AUTOSAR XML (schema 4-0-3)
standard types defined: Boolean, UInt32, UInt8
package /AUTOSAR_Platform/DataConstrs
  range DC_Boolean: raw 0..1
  range DC_UInt8: raw 0..255
package /PATAC/MSM/ComponentTypes
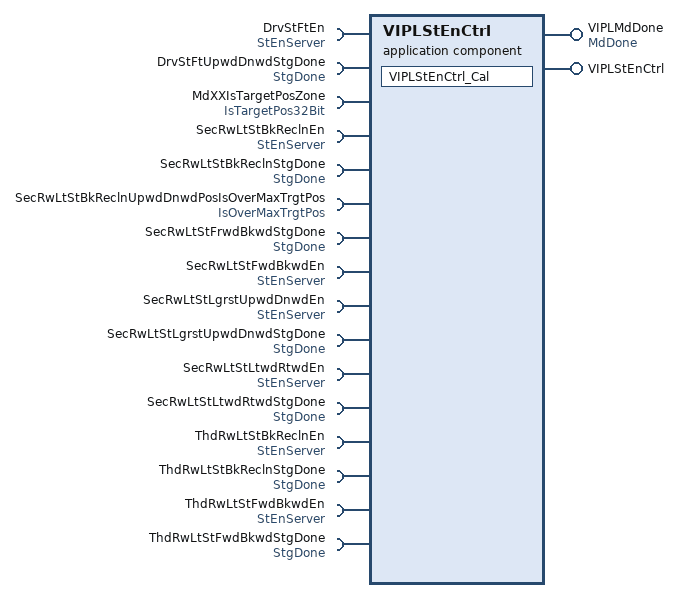
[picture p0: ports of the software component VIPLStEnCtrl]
  application sw component type VIPLStEnCtrl
    provide port VIPLMdDone: nonqueued-sender-com-spec{data-element=MdDone/Val, init-value=0}, provided-interface=MdDone
    provide port VIPLStEnCtrl: server-com-spec{operation=Cal, queue-length=1}, provided-interface=VIPLStEnCtrl
    16 x require port:
      DrvStFtEn: required-com-specs=[Clear, Get, Set], required-interface=StEnServer
      DrvStFtUpwdDnwdStgDone: nonqueued-receiver-com-spec{data-element=StgDone/Val, filter=data-filter-type=ALWAYS, init-value=0}, required-interface=StgDone
      MdXXIsTargetPosZone: nonqueued-receiver-com-spec{data-element=IsTargetPos32Bit/Val, filter=data-filter-type=ALWAYS, init-value=0}, required-interface=IsTargetPos32Bit
      SecRwLtStBkReclnEn: required-com-specs=[Clear, Get, Set], required-interface=StEnServer
      SecRwLtStBkReclnStgDone: nonqueued-receiver-com-spec{data-element=StgDone/Val, filter=data-filter-type=ALWAYS, init-value=0}, required-interface=StgDone
      SecRwLtStBkReclnUpwdDnwdPosIsOverMaxTrgtPos: nonqueued-receiver-com-spec{data-element=IsOverMaxTrgtPos/Val, filter=data-filter-type=ALWAYS, init-value=0}, required-interface=IsOverMaxTrgtPos
      SecRwLtStFrwdBkwdStgDone: nonqueued-receiver-com-spec{data-element=StgDone/Val, filter=data-filter-type=ALWAYS, init-value=0}, required-interface=StgDone
      SecRwLtStFwdBkwdEn: required-com-specs=[Clear, Get, Set], required-interface=StEnServer
      SecRwLtStLgrstUpwdDnwdEn: required-com-specs=[Clear, Get, Set], required-interface=StEnServer
      SecRwLtStLgrstUpwdDnwdStgDone: nonqueued-receiver-com-spec{data-element=StgDone/Val, filter=data-filter-type=ALWAYS, init-value=0}, required-interface=StgDone
      SecRwLtStLtwdRtwdEn: required-com-specs=[Clear, Get, Set], required-interface=StEnServer
      SecRwLtStLtwdRtwdStgDone: nonqueued-receiver-com-spec{data-element=StgDone/Val, filter=data-filter-type=ALWAYS, init-value=0}, required-interface=StgDone
      ThdRwLtStBkReclnEn: required-com-specs=[Clear, Get, Set], required-interface=StEnServer
      ThdRwLtStBkReclnStgDone: nonqueued-receiver-com-spec{data-element=StgDone/Val, filter=data-filter-type=ALWAYS, init-value=0}, required-interface=StgDone
      ThdRwLtStFwdBkwdEn: required-com-specs=[Clear, Get, Set], required-interface=StEnServer
      ThdRwLtStFwdBkwdStgDone: nonqueued-receiver-com-spec{data-element=StgDone/Val, filter=data-filter-type=ALWAYS, init-value=0}, required-interface=StgDone
    behavior VIPLStEnCtrl_InternalBehavior
      operation invoked event OIT_VIPLStEnCtrl_Cal_VIPLStEnCtrl_Cal: start-on-event=VIPLStEnCtrl_Cal, operation=VIPLStEnCtrl.Cal
      runnable VIPLStEnCtrl_Cal
        data-receive-point-by-arguments:
          9 x access:
            REC_DrvStFtUpwdDnwdStgDone_Val: accessed-variable=DrvStFtUpwdDnwdStgDone.Val
            REC_MdXXIsTargetPosZone_Val: accessed-variable=MdXXIsTargetPosZone.Val
            REC_SecRwLtStBkReclnStgDone_Val: accessed-variable=SecRwLtStBkReclnStgDone.Val
            REC_SecRwLtStBkReclnUpwdDnwdPosIsOverMaxTrgtPos_Val: accessed-variable=SecRwLtStBkReclnUpwdDnwdPosIsOverMaxTrgtPos.Val
            REC_SecRwLtStFrwdBkwdStgDone_Val: accessed-variable=SecRwLtStFrwdBkwdStgDone.Val
            REC_SecRwLtStLgrstUpwdDnwdStgDone_Val: accessed-variable=SecRwLtStLgrstUpwdDnwdStgDone.Val
            REC_SecRwLtStLtwdRtwdStgDone_Val: accessed-variable=SecRwLtStLtwdRtwdStgDone.Val
            REC_ThdRwLtStBkReclnStgDone_Val: accessed-variable=ThdRwLtStBkReclnStgDone.Val
            REC_ThdRwLtStFwdBkwdStgDone_Val: accessed-variable=ThdRwLtStFwdBkwdStgDone.Val
        data-send-points:
          access SEND_VIPLMdDone_Val: accessed-variable=VIPLMdDone.Val
        14 x sync call, all with timeout=0:
          SC_DrvStFtEn_Clear: operation=DrvStFtEn.Clear
          SC_DrvStFtEn_Set: operation=DrvStFtEn.Set
          SC_SecRwLtStBkReclnEn_Clear: operation=SecRwLtStBkReclnEn.Clear
          SC_SecRwLtStBkReclnEn_Set: operation=SecRwLtStBkReclnEn.Set
          SC_SecRwLtStFwdBkwdEn_Clear: operation=SecRwLtStFwdBkwdEn.Clear
          SC_SecRwLtStFwdBkwdEn_Set: operation=SecRwLtStFwdBkwdEn.Set
          SC_SecRwLtStLgrstUpwdDnwdEn_Clear: operation=SecRwLtStLgrstUpwdDnwdEn.Clear
          SC_SecRwLtStLgrstUpwdDnwdEn_Set: operation=SecRwLtStLgrstUpwdDnwdEn.Set
          SC_SecRwLtStLtwdRtwdEn_Clear: operation=SecRwLtStLtwdRtwdEn.Clear
          SC_SecRwLtStLtwdRtwdEn_Set: operation=SecRwLtStLtwdRtwdEn.Set
          SC_ThdRwLtStBkReclnEn_Clear: operation=ThdRwLtStBkReclnEn.Clear
          SC_ThdRwLtStBkReclnEn_Set: operation=ThdRwLtStBkReclnEn.Set
          SC_ThdRwLtStFwdBkwdEn_Clear: operation=ThdRwLtStFwdBkwdEn.Clear
          SC_ThdRwLtStFwdBkwdEn_Set: operation=ThdRwLtStFwdBkwdEn.Set
  swc implementation VIPLStEnCtrl_Implementation: behavior=VIPLStEnCtrl_InternalBehavior
    code-descriptors:
      code Default: artifact-descriptors=autosar-engineering-object={short-label=Default, category=SWSRC}
package /PATAC/MSM/ModeAdjust/PortInterface
  client server interface StEnServer
    operation Clear
      arg data: type=UInt8, direction=IN, server-argument-impl-policy=USE-ARGUMENT-TYPE
    operation Get
      arg data: type=UInt32, direction=OUT, server-argument-impl-policy=USE-ARGUMENT-TYPE
    operation Set
      arg data: type=UInt8, direction=IN, server-argument-impl-policy=USE-ARGUMENT-TYPE
  client server interface VIPLStEnCtrl
    operation Cal
  sender receiver interface IsTargetPos32Bit: invalidation-policy{data-element=IsTargetPos32Bit/Val, handle-invalid=DONT-INVALIDATE}
    data Val: type=UInt32
  sender receiver interface MdDone: invalidation-policy{data-element=MdDone/Val, handle-invalid=DONT-INVALIDATE}
    data Val: type=UInt8
  sender receiver interface StgDone: invalidation-policy{data-element=StgDone/Val, handle-invalid=DONT-INVALIDATE}
    data Val: type=Boolean
package /PortInterfaces
  sender receiver interface IsOverMaxTrgtPos: invalidation-policy{data-element=IsOverMaxTrgtPos/Val, handle-invalid=DONT-INVALIDATE}
    data Val: type=Boolean
